AUTOSAR XML (schema 4-2-2)
package /STELLANTIS/EPT/SASWCs
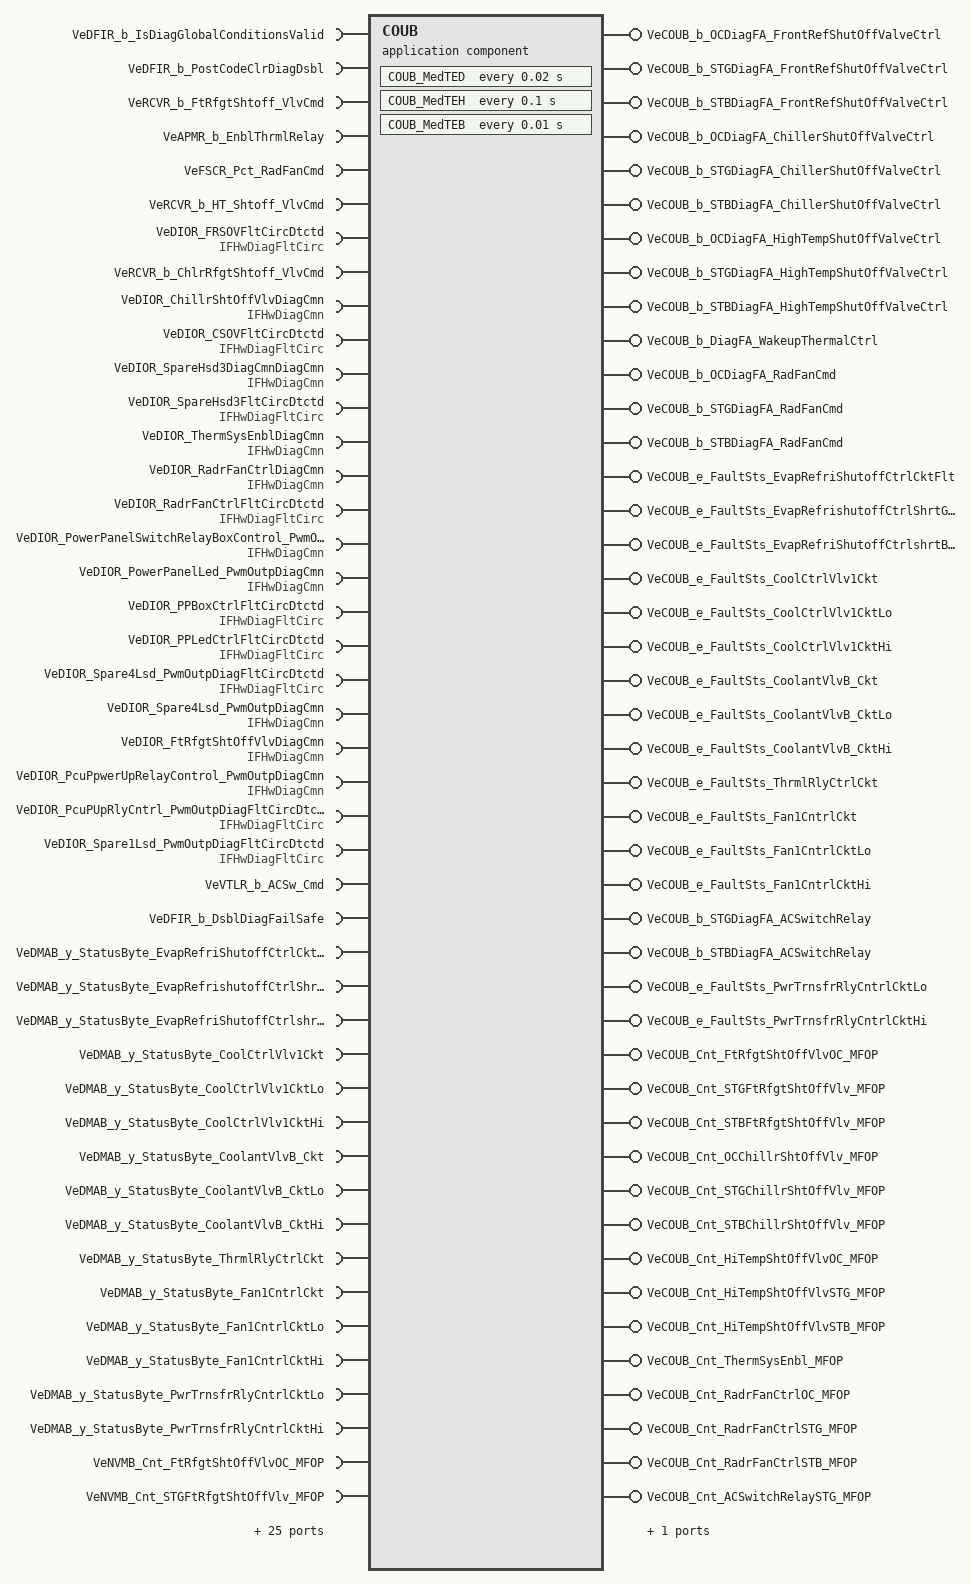
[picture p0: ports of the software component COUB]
  application sw component type COUB
    57 x require port:
      VeDFIR_b_IsDiagGlobalConditionsValid: variation-point={short-label=vpVeDFIR_b_IsDiagGlobalConditionsValid, sw-syscond=1}, nonqueued-receiver-com-spec{data-element=Value, init-value=0}, required-interface=VeDFIR_b_IsDiagGlobalConditionsValid
      VeDFIR_b_PostCodeClrDiagDsbl: variation-point={short-label=vpVeDFIR_b_PostCodeClrDiagDsbl, sw-syscond=1}, nonqueued-receiver-com-spec{data-element=Value, init-value=0}, required-interface=VeDFIR_b_PostCodeClrDiagDsbl
      VeRCVR_b_FtRfgtShtoff_VlvCmd: variation-point={short-label=vpVeRCVR_b_FtRfgtShtoff_VlvCmd, sw-syscond=1}, nonqueued-receiver-com-spec{data-element=Value, init-value=0}, required-interface=VeRCVR_b_FtRfgtShtoff_VlvCmd
      VeAPMR_b_EnblThrmlRelay: variation-point={short-label=vpVeAPMR_b_EnblThrmlRelay, sw-syscond=1}, nonqueued-receiver-com-spec{data-element=Value, init-value=0}, required-interface=VeAPMR_b_EnblThrmlRelay
      VeFSCR_Pct_RadFanCmd: variation-point={short-label=vpVeFSCR_Pct_RadFanCmd, sw-syscond=1}, nonqueued-receiver-com-spec{data-element=Value, init-value=0}, required-interface=VeFSCR_Pct_RadFanCmd
      VeRCVR_b_HT_Shtoff_VlvCmd: variation-point={short-label=vpVeRCVR_b_HT_Shtoff_VlvCmd, sw-syscond=1}, nonqueued-receiver-com-spec{data-element=Value, init-value=0}, required-interface=VeRCVR_b_HT_Shtoff_VlvCmd
      VeDIOR_FRSOVFltCircDtctd: variation-point={short-label=vpVeDIOR_FRSOVFltCircDtctd, sw-syscond=1}, required-interface=IFHwDiagFltCirc
        required-com-specs:
          {data-element=CircShoLo, init-value={short-label=DefaultInitValue_IDTCondPresence, fields=[0, 0, 0, 0, 0, 0, 0, 0]}}
          {data-element=CircShoHi, init-value={short-label=DefaultInitValue_IDTCondPresence, fields=[0, 0, 0, 0, 0, 0, 0, 0]}}
          {data-element=CircOpen, init-value={short-label=DefaultInitValue_IDTCondPresence, fields=[0, 0, 0, 0, 0, 0, 0, 0]}}
          {data-element=ShoLoad, init-value={short-label=DefaultInitValue_IDTCondPresence, fields=[0, 0, 0, 0, 0, 0, 0, 0]}}
      VeRCVR_b_ChlrRfgtShtoff_VlvCmd: variation-point={short-label=vpVeRCVR_b_ChlrRfgtShtoff_VlvCmd, sw-syscond=1}, nonqueued-receiver-com-spec{data-element=Value, init-value=0}, required-interface=VeRCVR_b_ChlrRfgtShtoff_VlvCmd
      VeDIOR_ChillrShtOffVlvDiagCmn: variation-point={short-label=vpVeDIOR_ChillrShtOffVlvDiagCmn, sw-syscond=1}, nonqueued-receiver-com-spec{data-element=b_FailrPrsnt, init-value=0}, required-interface=IFHwDiagCmn
      VeDIOR_CSOVFltCircDtctd: variation-point={short-label=vpVeDIOR_CSOVFltCircDtctd, sw-syscond=1}, required-interface=IFHwDiagFltCirc
        required-com-specs:
          {data-element=CircShoLo, init-value={short-label=DefaultInitValue_IDTCondPresence, fields=[0, 0, 0, 0, 0, 0, 0, 0]}}
          {data-element=CircShoHi, init-value={short-label=DefaultInitValue_IDTCondPresence, fields=[0, 0, 0, 0, 0, 0, 0, 0]}}
          {data-element=CircOpen, init-value={short-label=DefaultInitValue_IDTCondPresence, fields=[0, 0, 0, 0, 0, 0, 0, 0]}}
      VeDIOR_SpareHsd3DiagCmnDiagCmn: variation-point={short-label=vpVeDIOR_SpareHsd3DiagCmnDiagCmn, sw-syscond=1}, nonqueued-receiver-com-spec{data-element=b_FailrPrsnt, init-value=0}, required-interface=IFHwDiagCmn
      VeDIOR_SpareHsd3FltCircDtctd: variation-point={short-label=vpVeDIOR_SpareHsd3FltCircDtctd, sw-syscond=1}, required-interface=IFHwDiagFltCirc
        required-com-specs:
          {data-element=CircShoLo, init-value={short-label=DefaultInitValue_IDTCondPresence, fields=[0, 0, 0, 0, 0, 0, 0, 0]}}
          {data-element=CircShoHi, init-value={short-label=DefaultInitValue_IDTCondPresence, fields=[0, 0, 0, 0, 0, 0, 0, 0]}}
          {data-element=CircOpen, init-value={short-label=DefaultInitValue_IDTCondPresence, fields=[0, 0, 0, 0, 0, 0, 0, 0]}}
      VeDIOR_ThermSysEnblDiagCmn: variation-point={short-label=vpVeDIOR_ThermSysEnblDiagCmn, sw-syscond=1}, nonqueued-receiver-com-spec{data-element=b_FailrPrsnt, init-value=0}, required-interface=IFHwDiagCmn
      VeDIOR_RadrFanCtrlDiagCmn: variation-point={short-label=vpVeDIOR_RadrFanCtrlDiagCmn, sw-syscond=1}, nonqueued-receiver-com-spec{data-element=b_FailrPrsnt, init-value=0}, required-interface=IFHwDiagCmn
      VeDIOR_RadrFanCtrlFltCircDtctd: variation-point={short-label=vpVeDIOR_RadrFanCtrlFltCircDtctd, sw-syscond=1}, required-interface=IFHwDiagFltCirc
        required-com-specs:
          {data-element=CircShoLo, init-value={short-label=DefaultInitValue_IDTCondPresence, fields=[0, 0, 0, 0, 0, 0, 0, 0]}}
          {data-element=CircShoHi, init-value={short-label=DefaultInitValue_IDTCondPresence, fields=[0, 0, 0, 0, 0, 0, 0, 0]}}
          {data-element=CircOpen, init-value={short-label=DefaultInitValue_IDTCondPresence, fields=[0, 0, 0, 0, 0, 0, 0, 0]}}
      VeDIOR_PowerPanelSwitchRelayBoxControl_PwmOutpDiagCmn: nonqueued-receiver-com-spec{data-element=b_FailrPrsnt, init-value=0}, required-interface=IFHwDiagCmn
      VeDIOR_PowerPanelLed_PwmOutpDiagCmn: nonqueued-receiver-com-spec{data-element=b_FailrPrsnt, init-value=0}, required-interface=IFHwDiagCmn
      VeDIOR_PPBoxCtrlFltCircDtctd: required-interface=IFHwDiagFltCirc
        required-com-specs:
          {data-element=CircShoLo, init-value={short-label=DefaultInitValue_IDTCondPresence, fields=[0, 0, 0, 0, 0, 0, 0, 0]}}
          {data-element=CircShoHi, init-value={short-label=DefaultInitValue_IDTCondPresence, fields=[0, 0, 0, 0, 0, 0, 0, 0]}}
          {data-element=CircOpen, init-value={short-label=DefaultInitValue_IDTCondPresence, fields=[0, 0, 0, 0, 0, 0, 0, 0]}}
      VeDIOR_PPLedCtrlFltCircDtctd: required-interface=IFHwDiagFltCirc
        required-com-specs:
          {data-element=CircShoLo, init-value={short-label=DefaultInitValue_IDTCondPresence, fields=[0, 0, 0, 0, 0, 0, 0, 0]}}
          {data-element=CircShoHi, init-value={short-label=DefaultInitValue_IDTCondPresence, fields=[0, 0, 0, 0, 0, 0, 0, 0]}}
          {data-element=CircOpen, init-value={short-label=DefaultInitValue_IDTCondPresence, fields=[0, 0, 0, 0, 0, 0, 0, 0]}}
      VeDIOR_Spare4Lsd_PwmOutpDiagFltCircDtctd: variation-point={short-label=vpVeDIOR_Spare4Lsd_PwmOutpDiagFltCircDtctd, sw-syscond=1}, required-interface=IFHwDiagFltCirc
        required-com-specs:
          {data-element=CircShoLo, init-value={short-label=DefaultInitValue_IDTCondPresence, fields=[0, 0, 0, 0, 0, 0, 0, 0]}}
          {data-element=CircShoHi, init-value={short-label=DefaultInitValue_IDTCondPresence, fields=[0, 0, 0, 0, 0, 0, 0, 0]}}
          {data-element=CircOpen, init-value={short-label=DefaultInitValue_IDTCondPresence, fields=[0, 0, 0, 0, 0, 0, 0, 0]}}
      VeDIOR_Spare4Lsd_PwmOutpDiagCmn: variation-point={short-label=vpVeDIOR_Spare4Lsd_PwmOutpDiagCmn, sw-syscond=1}, nonqueued-receiver-com-spec{data-element=b_FailrPrsnt, init-value=0}, required-interface=IFHwDiagCmn
      VeDIOR_FtRfgtShtOffVlvDiagCmn: variation-point={short-label=vpVeDIOR_FtRfgtShtOffVlvDiagCmn, sw-syscond=1}, nonqueued-receiver-com-spec{data-element=b_FailrPrsnt, init-value=0}, required-interface=IFHwDiagCmn
      VeDIOR_PcuPpwerUpRelayControl_PwmOutpDiagCmn: nonqueued-receiver-com-spec{data-element=b_FailrPrsnt, init-value=0}, required-interface=IFHwDiagCmn
      VeDIOR_PcuPUpRlyCntrl_PwmOutpDiagFltCircDtctd: required-interface=IFHwDiagFltCirc
        required-com-specs:
          {data-element=CircShoLo, init-value={short-label=DefaultInitValue_IDTCondPresence, fields=[0, 0, 0, 0, 0, 0, 0, 0]}}
          {data-element=CircShoHi, init-value={short-label=DefaultInitValue_IDTCondPresence, fields=[0, 0, 0, 0, 0, 0, 0, 0]}}
          {data-element=CircOpen, init-value={short-label=DefaultInitValue_IDTCondPresence, fields=[0, 0, 0, 0, 0, 0, 0, 0]}}
      VeDIOR_Spare1Lsd_PwmOutpDiagFltCircDtctd: required-interface=IFHwDiagFltCirc
        required-com-specs:
          {data-element=CircShoLo, init-value={short-label=DefaultInitValue_IDTCondPresence, fields=[0, 0, 0, 0, 0, 0, 0, 0]}}
          {data-element=CircShoHi, init-value={short-label=DefaultInitValue_IDTCondPresence, fields=[0, 0, 0, 0, 0, 0, 0, 0]}}
          {data-element=CircOpen, init-value={short-label=DefaultInitValue_IDTCondPresence, fields=[0, 0, 0, 0, 0, 0, 0, 0]}}
      VeVTLR_b_ACSw_Cmd: variation-point={short-label=vpVeVTLR_b_ACSw_Cmd, sw-syscond=1}, nonqueued-receiver-com-spec{data-element=Value, init-value=0}, required-interface=VeVTLR_b_ACSw_Cmd
      VeDFIR_b_DsblDiagFailSafe: variation-point={short-label=vpVeDFIR_b_DsblDiagFailSafe, sw-syscond=1}, nonqueued-receiver-com-spec{data-element=Value, init-value=0}, required-interface=VeDFIR_b_DsblDiagFailSafe
      VeDMAB_y_StatusByte_EvapRefriShutoffCtrlCktFlt: variation-point={short-label=vpVeDMAB_y_StatusByte_EvapRefriShutoffCtrlCktFlt, sw-syscond=1}, nonqueued-receiver-com-spec{data-element=Value, init-value=0}, required-interface=VeDMAB_y_StatusByte_EvapRefriShutoffCtrlCktFlt
      VeDMAB_y_StatusByte_EvapRefrishutoffCtrlShrtGndFlt: variation-point={short-label=vpVeDMAB_y_StatusByte_EvapRefrishutoffCtrlShrtGndFlt, sw-syscond=1}, nonqueued-receiver-com-spec{data-element=Value, init-value=0}, required-interface=VeDMAB_y_StatusByte_EvapRefrishutoffCtrlShrtGndFlt
      VeDMAB_y_StatusByte_EvapRefriShutoffCtrlshrtBattFlt: variation-point={short-label=vpVeDMAB_y_StatusByte_EvapRefriShutoffCtrlshrtBattFlt, sw-syscond=1}, nonqueued-receiver-com-spec{data-element=Value, init-value=0}, required-interface=VeDMAB_y_StatusByte_EvapRefriShutoffCtrlshrtBattFlt
      VeDMAB_y_StatusByte_CoolCtrlVlv1Ckt: variation-point={short-label=vpVeDMAB_y_StatusByte_CoolCtrlVlv1Ckt, sw-syscond=1}, nonqueued-receiver-com-spec{data-element=Value, init-value=0}, required-interface=VeDMAB_y_StatusByte_CoolCtrlVlv1Ckt
      VeDMAB_y_StatusByte_CoolCtrlVlv1CktLo: variation-point={short-label=vpVeDMAB_y_StatusByte_CoolCtrlVlv1CktLo, sw-syscond=1}, nonqueued-receiver-com-spec{data-element=Value, init-value=0}, required-interface=VeDMAB_y_StatusByte_CoolCtrlVlv1CktLo
      VeDMAB_y_StatusByte_CoolCtrlVlv1CktHi: variation-point={short-label=vpVeDMAB_y_StatusByte_CoolCtrlVlv1CktHi, sw-syscond=1}, nonqueued-receiver-com-spec{data-element=Value, init-value=0}, required-interface=VeDMAB_y_StatusByte_CoolCtrlVlv1CktHi
      VeDMAB_y_StatusByte_CoolantVlvB_Ckt: variation-point={short-label=vpVeDMAB_y_StatusByte_CoolantVlvB_Ckt, sw-syscond=1}, nonqueued-receiver-com-spec{data-element=Value, init-value=0}, required-interface=VeDMAB_y_StatusByte_CoolantVlvB_Ckt
      VeDMAB_y_StatusByte_CoolantVlvB_CktLo: variation-point={short-label=vpVeDMAB_y_StatusByte_CoolantVlvB_CktLo, sw-syscond=1}, nonqueued-receiver-com-spec{data-element=Value, init-value=0}, required-interface=VeDMAB_y_StatusByte_CoolantVlvB_CktLo
      VeDMAB_y_StatusByte_CoolantVlvB_CktHi: variation-point={short-label=vpVeDMAB_y_StatusByte_CoolantVlvB_CktHi, sw-syscond=1}, nonqueued-receiver-com-spec{data-element=Value, init-value=0}, required-interface=VeDMAB_y_StatusByte_CoolantVlvB_CktHi
      VeDMAB_y_StatusByte_ThrmlRlyCtrlCkt: variation-point={short-label=vpVeDMAB_y_StatusByte_ThrmlRlyCtrlCkt, sw-syscond=1}, nonqueued-receiver-com-spec{data-element=Value, init-value=0}, required-interface=VeDMAB_y_StatusByte_ThrmlRlyCtrlCkt
      VeDMAB_y_StatusByte_Fan1CntrlCkt: variation-point={short-label=vpVeDMAB_y_StatusByte_Fan1CntrlCkt, sw-syscond=1}, nonqueued-receiver-com-spec{data-element=Value, init-value=0}, required-interface=VeDMAB_y_StatusByte_Fan1CntrlCkt
      VeDMAB_y_StatusByte_Fan1CntrlCktLo: variation-point={short-label=vpVeDMAB_y_StatusByte_Fan1CntrlCktLo, sw-syscond=1}, nonqueued-receiver-com-spec{data-element=Value, init-value=0}, required-interface=VeDMAB_y_StatusByte_Fan1CntrlCktLo
      VeDMAB_y_StatusByte_Fan1CntrlCktHi: variation-point={short-label=vpVeDMAB_y_StatusByte_Fan1CntrlCktHi, sw-syscond=1}, nonqueued-receiver-com-spec{data-element=Value, init-value=0}, required-interface=VeDMAB_y_StatusByte_Fan1CntrlCktHi
      VeDMAB_y_StatusByte_PwrTrnsfrRlyCntrlCktLo: variation-point={short-label=vpVeDMAB_y_StatusByte_PwrTrnsfrRlyCntrlCktLo, sw-syscond=1}, nonqueued-receiver-com-spec{data-element=Value, init-value=0}, required-interface=VeDMAB_y_StatusByte_PwrTrnsfrRlyCntrlCktLo
      VeDMAB_y_StatusByte_PwrTrnsfrRlyCntrlCktHi: variation-point={short-label=vpVeDMAB_y_StatusByte_PwrTrnsfrRlyCntrlCktHi, sw-syscond=1}, nonqueued-receiver-com-spec{data-element=Value, init-value=0}, required-interface=VeDMAB_y_StatusByte_PwrTrnsfrRlyCntrlCktHi
      VeNVMB_Cnt_FtRfgtShtOffVlvOC_MFOP: variation-point={short-label=vpVeNVMB_Cnt_FtRfgtShtOffVlvOC_MFOP, sw-syscond=1}, nonqueued-receiver-com-spec{data-element=Value, init-value=0}, required-interface=VeNVMB_Cnt_FtRfgtShtOffVlvOC_MFOP
      VeNVMB_Cnt_STGFtRfgtShtOffVlv_MFOP: variation-point={short-label=vpVeNVMB_Cnt_STGFtRfgtShtOffVlv_MFOP, sw-syscond=1}, nonqueued-receiver-com-spec{data-element=Value, init-value=0}, required-interface=VeNVMB_Cnt_STGFtRfgtShtOffVlv_MFOP
      VeNVMB_Cnt_STBFtRfgtShtOffVlv_MFOP: variation-point={short-label=vpVeNVMB_Cnt_STBFtRfgtShtOffVlv_MFOP, sw-syscond=1}, nonqueued-receiver-com-spec{data-element=Value, init-value=0}, required-interface=VeNVMB_Cnt_STBFtRfgtShtOffVlv_MFOP
      VeNVMB_Cnt_OCChillrShtOffVlv_MFOP: variation-point={short-label=vpVeNVMB_Cnt_OCChillrShtOffVlv_MFOP, sw-syscond=1}, nonqueued-receiver-com-spec{data-element=Value, init-value=0}, required-interface=VeNVMB_Cnt_OCChillrShtOffVlv_MFOP
      VeNVMB_Cnt_STGChillrShtOffVlv_MFOP: variation-point={short-label=vpVeNVMB_Cnt_STGChillrShtOffVlv_MFOP, sw-syscond=1}, nonqueued-receiver-com-spec{data-element=Value, init-value=0}, required-interface=VeNVMB_Cnt_STGChillrShtOffVlv_MFOP
      VeNVMB_Cnt_STBChillrShtOffVlv_MFOP: variation-point={short-label=vpVeNVMB_Cnt_STBChillrShtOffVlv_MFOP, sw-syscond=1}, nonqueued-receiver-com-spec{data-element=Value, init-value=0}, required-interface=VeNVMB_Cnt_STBChillrShtOffVlv_MFOP
      VeNVMB_Cnt_HiTempShtOffVlvOC_MFOP: variation-point={short-label=vpVeNVMB_Cnt_HiTempShtOffVlvOC_MFOP, sw-syscond=1}, nonqueued-receiver-com-spec{data-element=Value, init-value=0}, required-interface=VeNVMB_Cnt_HiTempShtOffVlvOC_MFOP
      VeNVMB_Cnt_HiTempShtOffVlvSTG_MFOP: variation-point={short-label=vpVeNVMB_Cnt_HiTempShtOffVlvSTG_MFOP, sw-syscond=1}, nonqueued-receiver-com-spec{data-element=Value, init-value=0}, required-interface=VeNVMB_Cnt_HiTempShtOffVlvSTG_MFOP
      VeNVMB_Cnt_HiTempShtOffVlvSTB_MFOP: variation-point={short-label=vpVeNVMB_Cnt_HiTempShtOffVlvSTB_MFOP, sw-syscond=1}, nonqueued-receiver-com-spec{data-element=Value, init-value=0}, required-interface=VeNVMB_Cnt_HiTempShtOffVlvSTB_MFOP
      VeNVMB_Cnt_ThermSysEnbl_MFOP: variation-point={short-label=vpVeNVMB_Cnt_ThermSysEnbl_MFOP, sw-syscond=1}, nonqueued-receiver-com-spec{data-element=Value, init-value=0}, required-interface=VeNVMB_Cnt_ThermSysEnbl_MFOP
      VeNVMB_Cnt_RadrFanCtrlOC_MFOP: variation-point={short-label=vpVeNVMB_Cnt_RadrFanCtrlOC_MFOP, sw-syscond=1}, nonqueued-receiver-com-spec{data-element=Value, init-value=0}, required-interface=VeNVMB_Cnt_RadrFanCtrlOC_MFOP
      VeNVMB_Cnt_RadrFanCtrlSTG_MFOP: variation-point={short-label=vpVeNVMB_Cnt_RadrFanCtrlSTG_MFOP, sw-syscond=1}, nonqueued-receiver-com-spec{data-element=Value, init-value=0}, required-interface=VeNVMB_Cnt_RadrFanCtrlSTG_MFOP
      VeNVMB_Cnt_RadrFanCtrlSTB_MFOP: variation-point={short-label=vpVeNVMB_Cnt_RadrFanCtrlSTB_MFOP, sw-syscond=1}, nonqueued-receiver-com-spec{data-element=Value, init-value=0}, required-interface=VeNVMB_Cnt_RadrFanCtrlSTB_MFOP
      VeNVMB_Cnt_ACSwitchRelaySTG_MFOP: variation-point={short-label=vpVeNVMB_Cnt_ACSwitchRelaySTG_MFOP, sw-syscond=1}, nonqueued-receiver-com-spec{data-element=Value, init-value=0}, required-interface=VeNVMB_Cnt_ACSwitchRelaySTG_MFOP
      VeNVMB_Cnt_ACSwitchRelaySTB_MFOP: variation-point={short-label=vpVeNVMB_Cnt_ACSwitchRelaySTB_MFOP, sw-syscond=1}, nonqueued-receiver-com-spec{data-element=Value, init-value=0}, required-interface=VeNVMB_Cnt_ACSwitchRelaySTB_MFOP
    45 x provide port:
      VeCOUB_b_OCDiagFA_FrontRefShutOffValveCtrl: variation-point={short-label=vpVeCOUB_b_OCDiagFA_FrontRefShutOffValveCtrl, sw-syscond=1}, nonqueued-sender-com-spec{data-element=Value, init-value=0}, provided-interface=VeCOUB_b_OCDiagFA_FrontRefShutOffValveCtrl
      VeCOUB_b_STGDiagFA_FrontRefShutOffValveCtrl: variation-point={short-label=vpVeCOUB_b_STGDiagFA_FrontRefShutOffValveCtrl, sw-syscond=1}, nonqueued-sender-com-spec{data-element=Value, init-value=0}, provided-interface=VeCOUB_b_STGDiagFA_FrontRefShutOffValveCtrl
      VeCOUB_b_STBDiagFA_FrontRefShutOffValveCtrl: variation-point={short-label=vpVeCOUB_b_STBDiagFA_FrontRefShutOffValveCtrl, sw-syscond=1}, nonqueued-sender-com-spec{data-element=Value, init-value=0}, provided-interface=VeCOUB_b_STBDiagFA_FrontRefShutOffValveCtrl
      VeCOUB_b_OCDiagFA_ChillerShutOffValveCtrl: variation-point={short-label=vpVeCOUB_b_OCDiagFA_ChillerShutOffValveCtrl, sw-syscond=1}, nonqueued-sender-com-spec{data-element=Value, init-value=0}, provided-interface=VeCOUB_b_OCDiagFA_ChillerShutOffValveCtrl
      VeCOUB_b_STGDiagFA_ChillerShutOffValveCtrl: variation-point={short-label=vpVeCOUB_b_STGDiagFA_ChillerShutOffValveCtrl, sw-syscond=1}, nonqueued-sender-com-spec{data-element=Value, init-value=0}, provided-interface=VeCOUB_b_STGDiagFA_ChillerShutOffValveCtrl
      VeCOUB_b_STBDiagFA_ChillerShutOffValveCtrl: variation-point={short-label=vpVeCOUB_b_STBDiagFA_ChillerShutOffValveCtrl, sw-syscond=1}, nonqueued-sender-com-spec{data-element=Value, init-value=0}, provided-interface=VeCOUB_b_STBDiagFA_ChillerShutOffValveCtrl
      VeCOUB_b_OCDiagFA_HighTempShutOffValveCtrl: variation-point={short-label=vpVeCOUB_b_OCDiagFA_HighTempShutOffValveCtrl, sw-syscond=1}, nonqueued-sender-com-spec{data-element=Value, init-value=0}, provided-interface=VeCOUB_b_OCDiagFA_HighTempShutOffValveCtrl
      VeCOUB_b_STGDiagFA_HighTempShutOffValveCtrl: variation-point={short-label=vpVeCOUB_b_STGDiagFA_HighTempShutOffValveCtrl, sw-syscond=1}, nonqueued-sender-com-spec{data-element=Value, init-value=0}, provided-interface=VeCOUB_b_STGDiagFA_HighTempShutOffValveCtrl
      VeCOUB_b_STBDiagFA_HighTempShutOffValveCtrl: variation-point={short-label=vpVeCOUB_b_STBDiagFA_HighTempShutOffValveCtrl, sw-syscond=1}, nonqueued-sender-com-spec{data-element=Value, init-value=0}, provided-interface=VeCOUB_b_STBDiagFA_HighTempShutOffValveCtrl
      VeCOUB_b_DiagFA_WakeupThermalCtrl: variation-point={short-label=vpVeCOUB_b_DiagFA_WakeupThermalCtrl, sw-syscond=1}, nonqueued-sender-com-spec{data-element=Value, init-value=0}, provided-interface=VeCOUB_b_DiagFA_WakeupThermalCtrl
      VeCOUB_b_OCDiagFA_RadFanCmd: variation-point={short-label=vpVeCOUB_b_OCDiagFA_RadFanCmd, sw-syscond=1}, nonqueued-sender-com-spec{data-element=Value, init-value=0}, provided-interface=VeCOUB_b_OCDiagFA_RadFanCmd
      VeCOUB_b_STGDiagFA_RadFanCmd: variation-point={short-label=vpVeCOUB_b_STGDiagFA_RadFanCmd, sw-syscond=1}, nonqueued-sender-com-spec{data-element=Value, init-value=0}, provided-interface=VeCOUB_b_STGDiagFA_RadFanCmd
      VeCOUB_b_STBDiagFA_RadFanCmd: variation-point={short-label=vpVeCOUB_b_STBDiagFA_RadFanCmd, sw-syscond=1}, nonqueued-sender-com-spec{data-element=Value, init-value=0}, provided-interface=VeCOUB_b_STBDiagFA_RadFanCmd
      VeCOUB_e_FaultSts_EvapRefriShutoffCtrlCktFlt: variation-point={short-label=vpVeCOUB_e_FaultSts_EvapRefriShutoffCtrlCktFlt, sw-syscond=1}, nonqueued-sender-com-spec{data-element=Value, init-value=CeDFIB_e_Init}, provided-interface=VeCOUB_e_FaultSts_EvapRefriShutoffCtrlCktFlt
      VeCOUB_e_FaultSts_EvapRefrishutoffCtrlShrtGndFlt: variation-point={short-label=vpVeCOUB_e_FaultSts_EvapRefrishutoffCtrlShrtGndFlt, sw-syscond=1}, nonqueued-sender-com-spec{data-element=Value, init-value=CeDFIB_e_Init}, provided-interface=VeCOUB_e_FaultSts_EvapRefrishutoffCtrlShrtGndFlt
      VeCOUB_e_FaultSts_EvapRefriShutoffCtrlshrtBattFlt: variation-point={short-label=vpVeCOUB_e_FaultSts_EvapRefriShutoffCtrlshrtBattFlt, sw-syscond=1}, nonqueued-sender-com-spec{data-element=Value, init-value=CeDFIB_e_Init}, provided-interface=VeCOUB_e_FaultSts_EvapRefriShutoffCtrlshrtBattFlt
      VeCOUB_e_FaultSts_CoolCtrlVlv1Ckt: variation-point={short-label=vpVeCOUB_e_FaultSts_CoolCtrlVlv1Ckt, sw-syscond=1}, nonqueued-sender-com-spec{data-element=Value, init-value=CeDFIB_e_Init}, provided-interface=VeCOUB_e_FaultSts_CoolCtrlVlv1Ckt
      VeCOUB_e_FaultSts_CoolCtrlVlv1CktLo: variation-point={short-label=vpVeCOUB_e_FaultSts_CoolCtrlVlv1CktLo, sw-syscond=1}, nonqueued-sender-com-spec{data-element=Value, init-value=CeDFIB_e_Init}, provided-interface=VeCOUB_e_FaultSts_CoolCtrlVlv1CktLo
      VeCOUB_e_FaultSts_CoolCtrlVlv1CktHi: variation-point={short-label=vpVeCOUB_e_FaultSts_CoolCtrlVlv1CktHi, sw-syscond=1}, nonqueued-sender-com-spec{data-element=Value, init-value=CeDFIB_e_Init}, provided-interface=VeCOUB_e_FaultSts_CoolCtrlVlv1CktHi
      VeCOUB_e_FaultSts_CoolantVlvB_Ckt: variation-point={short-label=vpVeCOUB_e_FaultSts_CoolantVlvB_Ckt, sw-syscond=1}, nonqueued-sender-com-spec{data-element=Value, init-value=CeDFIB_e_Init}, provided-interface=VeCOUB_e_FaultSts_CoolantVlvB_Ckt
      VeCOUB_e_FaultSts_CoolantVlvB_CktLo: variation-point={short-label=vpVeCOUB_e_FaultSts_CoolantVlvB_CktLo, sw-syscond=1}, nonqueued-sender-com-spec{data-element=Value, init-value=CeDFIB_e_Init}, provided-interface=VeCOUB_e_FaultSts_CoolantVlvB_CktLo
      VeCOUB_e_FaultSts_CoolantVlvB_CktHi: variation-point={short-label=vpVeCOUB_e_FaultSts_CoolantVlvB_CktHi, sw-syscond=1}, nonqueued-sender-com-spec{data-element=Value, init-value=CeDFIB_e_Init}, provided-interface=VeCOUB_e_FaultSts_CoolantVlvB_CktHi
      VeCOUB_e_FaultSts_ThrmlRlyCtrlCkt: variation-point={short-label=vpVeCOUB_e_FaultSts_ThrmlRlyCtrlCkt, sw-syscond=1}, nonqueued-sender-com-spec{data-element=Value, init-value=CeDFIB_e_Init}, provided-interface=VeCOUB_e_FaultSts_ThrmlRlyCtrlCkt
      VeCOUB_e_FaultSts_Fan1CntrlCkt: variation-point={short-label=vpVeCOUB_e_FaultSts_Fan1CntrlCkt, sw-syscond=1}, nonqueued-sender-com-spec{data-element=Value, init-value=CeDFIB_e_Init}, provided-interface=VeCOUB_e_FaultSts_Fan1CntrlCkt
      VeCOUB_e_FaultSts_Fan1CntrlCktLo: variation-point={short-label=vpVeCOUB_e_FaultSts_Fan1CntrlCktLo, sw-syscond=1}, nonqueued-sender-com-spec{data-element=Value, init-value=CeDFIB_e_Init}, provided-interface=VeCOUB_e_FaultSts_Fan1CntrlCktLo
      VeCOUB_e_FaultSts_Fan1CntrlCktHi: variation-point={short-label=vpVeCOUB_e_FaultSts_Fan1CntrlCktHi, sw-syscond=1}, nonqueued-sender-com-spec{data-element=Value, init-value=CeDFIB_e_Init}, provided-interface=VeCOUB_e_FaultSts_Fan1CntrlCktHi
      VeCOUB_b_STGDiagFA_ACSwitchRelay: variation-point={short-label=vpVeCOUB_b_STGDiagFA_ACSwitchRelay, sw-syscond=1}, nonqueued-sender-com-spec{data-element=Value, init-value=0}, provided-interface=VeCOUB_b_STGDiagFA_ACSwitchRelay
      VeCOUB_b_STBDiagFA_ACSwitchRelay: variation-point={short-label=vpVeCOUB_b_STBDiagFA_ACSwitchRelay, sw-syscond=1}, nonqueued-sender-com-spec{data-element=Value, init-value=0}, provided-interface=VeCOUB_b_STBDiagFA_ACSwitchRelay
      VeCOUB_e_FaultSts_PwrTrnsfrRlyCntrlCktLo: variation-point={short-label=vpVeCOUB_e_FaultSts_PwrTrnsfrRlyCntrlCktLo, sw-syscond=1}, nonqueued-sender-com-spec{data-element=Value, init-value=CeDFIB_e_Init}, provided-interface=VeCOUB_e_FaultSts_PwrTrnsfrRlyCntrlCktLo
      VeCOUB_e_FaultSts_PwrTrnsfrRlyCntrlCktHi: variation-point={short-label=vpVeCOUB_e_FaultSts_PwrTrnsfrRlyCntrlCktHi, sw-syscond=1}, nonqueued-sender-com-spec{data-element=Value, init-value=CeDFIB_e_Init}, provided-interface=VeCOUB_e_FaultSts_PwrTrnsfrRlyCntrlCktHi
      VeCOUB_Cnt_FtRfgtShtOffVlvOC_MFOP: variation-point={short-label=vpVeCOUB_Cnt_FtRfgtShtOffVlvOC_MFOP, sw-syscond=1}, nonqueued-sender-com-spec{data-element=Value, init-value=0}, provided-interface=VeCOUB_Cnt_FtRfgtShtOffVlvOC_MFOP
      VeCOUB_Cnt_STGFtRfgtShtOffVlv_MFOP: variation-point={short-label=vpVeCOUB_Cnt_STGFtRfgtShtOffVlv_MFOP, sw-syscond=1}, nonqueued-sender-com-spec{data-element=Value, init-value=0}, provided-interface=VeCOUB_Cnt_STGFtRfgtShtOffVlv_MFOP
      VeCOUB_Cnt_STBFtRfgtShtOffVlv_MFOP: variation-point={short-label=vpVeCOUB_Cnt_STBFtRfgtShtOffVlv_MFOP, sw-syscond=1}, nonqueued-sender-com-spec{data-element=Value, init-value=0}, provided-interface=VeCOUB_Cnt_STBFtRfgtShtOffVlv_MFOP
      VeCOUB_Cnt_OCChillrShtOffVlv_MFOP: variation-point={short-label=vpVeCOUB_Cnt_OCChillrShtOffVlv_MFOP, sw-syscond=1}, nonqueued-sender-com-spec{data-element=Value, init-value=0}, provided-interface=VeCOUB_Cnt_OCChillrShtOffVlv_MFOP
      VeCOUB_Cnt_STGChillrShtOffVlv_MFOP: variation-point={short-label=vpVeCOUB_Cnt_STGChillrShtOffVlv_MFOP, sw-syscond=1}, nonqueued-sender-com-spec{data-element=Value, init-value=0}, provided-interface=VeCOUB_Cnt_STGChillrShtOffVlv_MFOP
      VeCOUB_Cnt_STBChillrShtOffVlv_MFOP: variation-point={short-label=vpVeCOUB_Cnt_STBChillrShtOffVlv_MFOP, sw-syscond=1}, nonqueued-sender-com-spec{data-element=Value, init-value=0}, provided-interface=VeCOUB_Cnt_STBChillrShtOffVlv_MFOP
      VeCOUB_Cnt_HiTempShtOffVlvOC_MFOP: variation-point={short-label=vpVeCOUB_Cnt_HiTempShtOffVlvOC_MFOP, sw-syscond=1}, nonqueued-sender-com-spec{data-element=Value, init-value=0}, provided-interface=VeCOUB_Cnt_HiTempShtOffVlvOC_MFOP
      VeCOUB_Cnt_HiTempShtOffVlvSTG_MFOP: variation-point={short-label=vpVeCOUB_Cnt_HiTempShtOffVlvSTG_MFOP, sw-syscond=1}, nonqueued-sender-com-spec{data-element=Value, init-value=0}, provided-interface=VeCOUB_Cnt_HiTempShtOffVlvSTG_MFOP
      VeCOUB_Cnt_HiTempShtOffVlvSTB_MFOP: variation-point={short-label=vpVeCOUB_Cnt_HiTempShtOffVlvSTB_MFOP, sw-syscond=1}, nonqueued-sender-com-spec{data-element=Value, init-value=0}, provided-interface=VeCOUB_Cnt_HiTempShtOffVlvSTB_MFOP
      VeCOUB_Cnt_ThermSysEnbl_MFOP: variation-point={short-label=vpVeCOUB_Cnt_ThermSysEnbl_MFOP, sw-syscond=1}, nonqueued-sender-com-spec{data-element=Value, init-value=0}, provided-interface=VeCOUB_Cnt_ThermSysEnbl_MFOP
      VeCOUB_Cnt_RadrFanCtrlOC_MFOP: variation-point={short-label=vpVeCOUB_Cnt_RadrFanCtrlOC_MFOP, sw-syscond=1}, nonqueued-sender-com-spec{data-element=Value, init-value=0}, provided-interface=VeCOUB_Cnt_RadrFanCtrlOC_MFOP
      VeCOUB_Cnt_RadrFanCtrlSTG_MFOP: variation-point={short-label=vpVeCOUB_Cnt_RadrFanCtrlSTG_MFOP, sw-syscond=1}, nonqueued-sender-com-spec{data-element=Value, init-value=0}, provided-interface=VeCOUB_Cnt_RadrFanCtrlSTG_MFOP
      VeCOUB_Cnt_RadrFanCtrlSTB_MFOP: variation-point={short-label=vpVeCOUB_Cnt_RadrFanCtrlSTB_MFOP, sw-syscond=1}, nonqueued-sender-com-spec{data-element=Value, init-value=0}, provided-interface=VeCOUB_Cnt_RadrFanCtrlSTB_MFOP
      VeCOUB_Cnt_ACSwitchRelaySTG_MFOP: variation-point={short-label=vpVeCOUB_Cnt_ACSwitchRelaySTG_MFOP, sw-syscond=1}, nonqueued-sender-com-spec{data-element=Value, init-value=0}, provided-interface=VeCOUB_Cnt_ACSwitchRelaySTG_MFOP
      VeCOUB_Cnt_ACSwitchRelaySTB_MFOP: variation-point={short-label=vpVeCOUB_Cnt_ACSwitchRelaySTB_MFOP, sw-syscond=1}, nonqueued-sender-com-spec{data-element=Value, init-value=0}, provided-interface=VeCOUB_Cnt_ACSwitchRelaySTB_MFOP
    12 x require port:
      SetDIOR_b_ChillrShtOffVlv: variation-point={short-label=vpSetDIOR_b_ChillrShtOffVlv, sw-syscond=1}, client-com-spec=St, required-interface=IFIoHwAbDigOutpSetSt
      SetDIOR_b_FrntRefrigShtOffVlv: variation-point={short-label=vpSetDIOR_b_FrntRefrigShtOffVlv, sw-syscond=1}, client-com-spec=St, required-interface=IFIoHwAbDigOutpSetSt
      SetDIOR_b_SpareHsd3OutpSt: variation-point={short-label=vpSetDIOR_b_SpareHsd3OutpSt, sw-syscond=1}, client-com-spec=St, required-interface=IFIoHwAbDigOutpSetSt
      SetDIOR_b_ThermSysEnbl: variation-point={short-label=vpSetDIOR_b_ThermSysEnbl, sw-syscond=1}, client-com-spec=St, required-interface=IFIoHwAbDigOutpSetSt
      COUB_MedTEH_StartCheckpoint: client-com-spec=CheckpointReached, required-interface=WdgM_LocalSupervision
      COUB_MedTEH_StopCheckpoint: client-com-spec=CheckpointReached, required-interface=WdgM_LocalSupervision
      COUB_MedTEB_StartCheckpoint: client-com-spec=CheckpointReached, required-interface=WdgM_LocalSupervision
      COUB_MedTEB_StopCheckpoint: client-com-spec=CheckpointReached, required-interface=WdgM_LocalSupervision
      COUB_MedTED_StartCheckpoint: client-com-spec=CheckpointReached, required-interface=WdgM_LocalSupervision
      COUB_MedTED_StopCheckpoint: client-com-spec=CheckpointReached, required-interface=WdgM_LocalSupervision
      SetDIOR_e_Spare4Lsd_PwmOutpOps: variation-point={short-label=vpSetDIOR_e_Spare4Lsd_PwmOutpOps, sw-syscond=1}, client-com-spec=SetDIOR_PWM_DC, required-interface=IFIoHwAbPWMOutpSet
      SetDIOR_e_RadrFanCtrl: variation-point={short-label=vpSetDIOR_e_RadrFanCtrl, sw-syscond=1}, client-com-spec=SetDIOR_PWM_DC, required-interface=IFIoHwAbPWMOutpSet
    behavior IB_COUB: data-type-mapping=[msADTtoIDTMapping, ADTtoIDTMapping], handle-termination-and-restart=NO-SUPPORT
      timing event Event_MedTED: start-on-event=COUB_MedTED, period=0.02
      timing event Event_MedTEH: start-on-event=COUB_MedTEH, period=0.1
      timing event Event_MedTEB: start-on-event=COUB_MedTEB, period=0.01
      init event Event_COUB_ac_Init: start-on-event=COUB_ac_Init
      4 x runnable:
        COUB_ac_Init
          data-send-points:
            15 x access:
              OUT_VeCOUB_e_FaultSts_EvapRefriShutoffCtrlCktFlt_Value: accessed-variable=VeCOUB_e_FaultSts_EvapRefriShutoffCtrlCktFlt.Value, variation-point={short-label=vpOUT_VeCOUB_e_FaultSts_EvapRefriShutoffCtrlCktFlt_Value, sw-syscond=1}
              OUT_VeCOUB_e_FaultSts_EvapRefrishutoffCtrlShrtGndFlt_Value: accessed-variable=VeCOUB_e_FaultSts_EvapRefrishutoffCtrlShrtGndFlt.Value, variation-point={short-label=vpOUT_VeCOUB_e_FaultSts_EvapRefrishutoffCtrlShrtGndFlt_Value, sw-syscond=1}
              OUT_VeCOUB_e_FaultSts_EvapRefriShutoffCtrlshrtBattFlt_Value: accessed-variable=VeCOUB_e_FaultSts_EvapRefriShutoffCtrlshrtBattFlt.Value, variation-point={short-label=vpOUT_VeCOUB_e_FaultSts_EvapRefriShutoffCtrlshrtBattFlt_Value, sw-syscond=1}
              OUT_VeCOUB_e_FaultSts_CoolCtrlVlv1Ckt_Value: accessed-variable=VeCOUB_e_FaultSts_CoolCtrlVlv1Ckt.Value, variation-point={short-label=vpOUT_VeCOUB_e_FaultSts_CoolCtrlVlv1Ckt_Value, sw-syscond=1}
              OUT_VeCOUB_e_FaultSts_CoolCtrlVlv1CktLo_Value: accessed-variable=VeCOUB_e_FaultSts_CoolCtrlVlv1CktLo.Value, variation-point={short-label=vpOUT_VeCOUB_e_FaultSts_CoolCtrlVlv1CktLo_Value, sw-syscond=1}
              OUT_VeCOUB_e_FaultSts_CoolCtrlVlv1CktHi_Value: accessed-variable=VeCOUB_e_FaultSts_CoolCtrlVlv1CktHi.Value, variation-point={short-label=vpOUT_VeCOUB_e_FaultSts_CoolCtrlVlv1CktHi_Value, sw-syscond=1}
              OUT_VeCOUB_e_FaultSts_CoolantVlvB_Ckt_Value: accessed-variable=VeCOUB_e_FaultSts_CoolantVlvB_Ckt.Value, variation-point={short-label=vpOUT_VeCOUB_e_FaultSts_CoolantVlvB_Ckt_Value, sw-syscond=1}
              OUT_VeCOUB_e_FaultSts_CoolantVlvB_CktLo_Value: accessed-variable=VeCOUB_e_FaultSts_CoolantVlvB_CktLo.Value, variation-point={short-label=vpOUT_VeCOUB_e_FaultSts_CoolantVlvB_CktLo_Value, sw-syscond=1}
              OUT_VeCOUB_e_FaultSts_CoolantVlvB_CktHi_Value: accessed-variable=VeCOUB_e_FaultSts_CoolantVlvB_CktHi.Value, variation-point={short-label=vpOUT_VeCOUB_e_FaultSts_CoolantVlvB_CktHi_Value, sw-syscond=1}
              OUT_VeCOUB_e_FaultSts_ThrmlRlyCtrlCkt_Value: accessed-variable=VeCOUB_e_FaultSts_ThrmlRlyCtrlCkt.Value, variation-point={short-label=vpOUT_VeCOUB_e_FaultSts_ThrmlRlyCtrlCkt_Value, sw-syscond=1}
              OUT_VeCOUB_e_FaultSts_Fan1CntrlCkt_Value: accessed-variable=VeCOUB_e_FaultSts_Fan1CntrlCkt.Value, variation-point={short-label=vpOUT_VeCOUB_e_FaultSts_Fan1CntrlCkt_Value, sw-syscond=1}
              OUT_VeCOUB_e_FaultSts_Fan1CntrlCktLo_Value: accessed-variable=VeCOUB_e_FaultSts_Fan1CntrlCktLo.Value, variation-point={short-label=vpOUT_VeCOUB_e_FaultSts_Fan1CntrlCktLo_Value, sw-syscond=1}
              OUT_VeCOUB_e_FaultSts_Fan1CntrlCktHi_Value: accessed-variable=VeCOUB_e_FaultSts_Fan1CntrlCktHi.Value, variation-point={short-label=vpOUT_VeCOUB_e_FaultSts_Fan1CntrlCktHi_Value, sw-syscond=1}
              OUT_VeCOUB_e_FaultSts_PwrTrnsfrRlyCntrlCktLo_Value: accessed-variable=VeCOUB_e_FaultSts_PwrTrnsfrRlyCntrlCktLo.Value, variation-point={short-label=vpOUT_VeCOUB_e_FaultSts_PwrTrnsfrRlyCntrlCktLo_Value, sw-syscond=1}
              OUT_VeCOUB_e_FaultSts_PwrTrnsfrRlyCntrlCktHi_Value: accessed-variable=VeCOUB_e_FaultSts_PwrTrnsfrRlyCntrlCktHi.Value, variation-point={short-label=vpOUT_VeCOUB_e_FaultSts_PwrTrnsfrRlyCntrlCktHi_Value, sw-syscond=1}
          10 x sync call, all with timeout=1E-06:
            SC_SetDIOR_b_ChillrShtOffVlv_St: operation=SetDIOR_b_ChillrShtOffVlv.St, variation-point={short-label=vpSC_SetDIOR_b_ChillrShtOffVlv_St, sw-syscond=1}
            SC_SetDIOR_b_FrntRefrigShtOffVlv_St: operation=SetDIOR_b_FrntRefrigShtOffVlv.St, variation-point={short-label=vpSC_SetDIOR_b_FrntRefrigShtOffVlv_St, sw-syscond=1}
            SC_SetDIOR_b_SpareHsd3OutpSt_St: operation=SetDIOR_b_SpareHsd3OutpSt.St, variation-point={short-label=vpSC_SetDIOR_b_SpareHsd3OutpSt_St, sw-syscond=1}
            SC_SetDIOR_b_ThermSysEnbl_St: operation=SetDIOR_b_ThermSysEnbl.St, variation-point={short-label=vpSC_SetDIOR_b_ThermSysEnbl_St, sw-syscond=1}
            SC_SetDIOR_e_RadrFanCtrl_SetDIOR_PWM_Pol: operation=SetDIOR_e_RadrFanCtrl.SetDIOR_PWM_Pol, variation-point={short-label=vpSC_SetDIOR_e_RadrFanCtrl_SetDIOR_PWM_Pol, sw-syscond=1}
            SC_SetDIOR_e_RadrFanCtrl_SetDIOR_PWM_Prd: operation=SetDIOR_e_RadrFanCtrl.SetDIOR_PWM_Prd, variation-point={short-label=vpSC_SetDIOR_e_RadrFanCtrl_SetDIOR_PWM_Prd, sw-syscond=1}
            SC_SetDIOR_e_RadrFanCtrl_SetEnblSt: operation=SetDIOR_e_RadrFanCtrl.SetEnblSt, variation-point={short-label=vpSC_SetDIOR_e_RadrFanCtrl_SetEnblSt, sw-syscond=1}
            SC_SetDIOR_e_Spare4Lsd_PwmOutpOps_SetDIOR_PWM_Pol: operation=SetDIOR_e_Spare4Lsd_PwmOutpOps.SetDIOR_PWM_Pol, variation-point={short-label=vpSC_SetDIOR_e_Spare4Lsd_PwmOutpOps_SetDIOR_PWM_Pol, sw-syscond=1}
            SC_SetDIOR_e_Spare4Lsd_PwmOutpOps_SetDIOR_PWM_Prd: operation=SetDIOR_e_Spare4Lsd_PwmOutpOps.SetDIOR_PWM_Prd, variation-point={short-label=vpSC_SetDIOR_e_Spare4Lsd_PwmOutpOps_SetDIOR_PWM_Prd, sw-syscond=1}
            SC_SetDIOR_e_Spare4Lsd_PwmOutpOps_SetEnblSt: operation=SetDIOR_e_Spare4Lsd_PwmOutpOps.SetEnblSt, variation-point={short-label=vpSC_SetDIOR_e_Spare4Lsd_PwmOutpOps_SetEnblSt, sw-syscond=1}
        COUB_MedTED
          data-receive-point-by-arguments:
            36 x access:
              IN_VeDFIR_b_DsblDiagFailSafe_Value: accessed-variable=VeDFIR_b_DsblDiagFailSafe.Value, variation-point={short-label=vpIN_VeDFIR_b_DsblDiagFailSafe_Value, sw-syscond=1}
              IN_VeDFIR_b_IsDiagGlobalConditionsValid_Value: accessed-variable=VeDFIR_b_IsDiagGlobalConditionsValid.Value, variation-point={short-label=vpIN_VeDFIR_b_IsDiagGlobalConditionsValid_Value, sw-syscond=1}
              IN_VeDFIR_b_PostCodeClrDiagDsbl_Value: accessed-variable=VeDFIR_b_PostCodeClrDiagDsbl.Value, variation-point={short-label=vpIN_VeDFIR_b_PostCodeClrDiagDsbl_Value, sw-syscond=1}
              IN_VeDIOR_CSOVFltCircDtctd_CircOpen: accessed-variable=VeDIOR_CSOVFltCircDtctd.CircOpen, variation-point={short-label=vpIN_VeDIOR_CSOVFltCircDtctd_CircOpen, sw-syscond=1}
              IN_VeDIOR_CSOVFltCircDtctd_CircShoHi: accessed-variable=VeDIOR_CSOVFltCircDtctd.CircShoHi, variation-point={short-label=vpIN_VeDIOR_CSOVFltCircDtctd_CircShoHi, sw-syscond=1}
              IN_VeDIOR_CSOVFltCircDtctd_CircShoLo: accessed-variable=VeDIOR_CSOVFltCircDtctd.CircShoLo, variation-point={short-label=vpIN_VeDIOR_CSOVFltCircDtctd_CircShoLo, sw-syscond=1}
              IN_VeDIOR_ChillrShtOffVlvDiagCmn_b_FailrPrsnt: accessed-variable=VeDIOR_ChillrShtOffVlvDiagCmn.b_FailrPrsnt, variation-point={short-label=vpIN_VeDIOR_ChillrShtOffVlvDiagCmn_b_FailrPrsnt, sw-syscond=1}
              IN_VeDIOR_FRSOVFltCircDtctd_CircOpen: accessed-variable=VeDIOR_FRSOVFltCircDtctd.CircOpen, variation-point={short-label=vpIN_VeDIOR_FRSOVFltCircDtctd_CircOpen, sw-syscond=1}
              IN_VeDIOR_FRSOVFltCircDtctd_CircShoHi: accessed-variable=VeDIOR_FRSOVFltCircDtctd.CircShoHi, variation-point={short-label=vpIN_VeDIOR_FRSOVFltCircDtctd_CircShoHi, sw-syscond=1}
              IN_VeDIOR_FRSOVFltCircDtctd_CircShoLo: accessed-variable=VeDIOR_FRSOVFltCircDtctd.CircShoLo, variation-point={short-label=vpIN_VeDIOR_FRSOVFltCircDtctd_CircShoLo, sw-syscond=1}
              IN_VeDIOR_FtRfgtShtOffVlvDiagCmn_b_FailrPrsnt: accessed-variable=VeDIOR_FtRfgtShtOffVlvDiagCmn.b_FailrPrsnt, variation-point={short-label=vpIN_VeDIOR_FtRfgtShtOffVlvDiagCmn_b_FailrPrsnt, sw-syscond=1}
              IN_VeDIOR_SpareHsd3DiagCmnDiagCmn_b_FailrPrsnt: accessed-variable=VeDIOR_SpareHsd3DiagCmnDiagCmn.b_FailrPrsnt, variation-point={short-label=vpIN_VeDIOR_SpareHsd3DiagCmnDiagCmn_b_FailrPrsnt, sw-syscond=1}
              IN_VeDIOR_SpareHsd3FltCircDtctd_CircOpen: accessed-variable=VeDIOR_SpareHsd3FltCircDtctd.CircOpen, variation-point={short-label=vpIN_VeDIOR_SpareHsd3FltCircDtctd_CircOpen, sw-syscond=1}
              IN_VeDIOR_SpareHsd3FltCircDtctd_CircShoHi: accessed-variable=VeDIOR_SpareHsd3FltCircDtctd.CircShoHi, variation-point={short-label=vpIN_VeDIOR_SpareHsd3FltCircDtctd_CircShoHi, sw-syscond=1}
              IN_VeDIOR_SpareHsd3FltCircDtctd_CircShoLo: accessed-variable=VeDIOR_SpareHsd3FltCircDtctd.CircShoLo, variation-point={short-label=vpIN_VeDIOR_SpareHsd3FltCircDtctd_CircShoLo, sw-syscond=1}
              IN_VeDMAB_y_StatusByte_CoolCtrlVlv1Ckt_Value: accessed-variable=VeDMAB_y_StatusByte_CoolCtrlVlv1Ckt.Value, variation-point={short-label=vpIN_VeDMAB_y_StatusByte_CoolCtrlVlv1Ckt_Value, sw-syscond=1}
              IN_VeDMAB_y_StatusByte_CoolCtrlVlv1CktHi_Value: accessed-variable=VeDMAB_y_StatusByte_CoolCtrlVlv1CktHi.Value, variation-point={short-label=vpIN_VeDMAB_y_StatusByte_CoolCtrlVlv1CktHi_Value, sw-syscond=1}
              IN_VeDMAB_y_StatusByte_CoolCtrlVlv1CktLo_Value: accessed-variable=VeDMAB_y_StatusByte_CoolCtrlVlv1CktLo.Value, variation-point={short-label=vpIN_VeDMAB_y_StatusByte_CoolCtrlVlv1CktLo_Value, sw-syscond=1}
              IN_VeDMAB_y_StatusByte_CoolantVlvB_Ckt_Value: accessed-variable=VeDMAB_y_StatusByte_CoolantVlvB_Ckt.Value, variation-point={short-label=vpIN_VeDMAB_y_StatusByte_CoolantVlvB_Ckt_Value, sw-syscond=1}
              IN_VeDMAB_y_StatusByte_CoolantVlvB_CktHi_Value: accessed-variable=VeDMAB_y_StatusByte_CoolantVlvB_CktHi.Value, variation-point={short-label=vpIN_VeDMAB_y_StatusByte_CoolantVlvB_CktHi_Value, sw-syscond=1}
              IN_VeDMAB_y_StatusByte_CoolantVlvB_CktLo_Value: accessed-variable=VeDMAB_y_StatusByte_CoolantVlvB_CktLo.Value, variation-point={short-label=vpIN_VeDMAB_y_StatusByte_CoolantVlvB_CktLo_Value, sw-syscond=1}
              IN_VeDMAB_y_StatusByte_EvapRefriShutoffCtrlCktFlt_Value: accessed-variable=VeDMAB_y_StatusByte_EvapRefriShutoffCtrlCktFlt.Value, variation-point={short-label=vpIN_VeDMAB_y_StatusByte_EvapRefriShutoffCtrlCktFlt_Value, sw-syscond=1}
              IN_VeDMAB_y_StatusByte_EvapRefriShutoffCtrlshrtBattFlt_Value: accessed-variable=VeDMAB_y_StatusByte_EvapRefriShutoffCtrlshrtBattFlt.Value, variation-point={short-label=vpIN_VeDMAB_y_StatusByte_EvapRefriShutoffCtrlshrtBattFlt_Value, sw-syscond=1}
              IN_VeDMAB_y_StatusByte_EvapRefrishutoffCtrlShrtGndFlt_Value: accessed-variable=VeDMAB_y_StatusByte_EvapRefrishutoffCtrlShrtGndFlt.Value, variation-point={short-label=vpIN_VeDMAB_y_StatusByte_EvapRefrishutoffCtrlShrtGndFlt_Value, sw-syscond=1}
              IN_VeNVMB_Cnt_FtRfgtShtOffVlvOC_MFOP_Value: accessed-variable=VeNVMB_Cnt_FtRfgtShtOffVlvOC_MFOP.Value, variation-point={short-label=vpIN_VeNVMB_Cnt_FtRfgtShtOffVlvOC_MFOP_Value, sw-syscond=1}
              IN_VeNVMB_Cnt_HiTempShtOffVlvOC_MFOP_Value: accessed-variable=VeNVMB_Cnt_HiTempShtOffVlvOC_MFOP.Value, variation-point={short-label=vpIN_VeNVMB_Cnt_HiTempShtOffVlvOC_MFOP_Value, sw-syscond=1}
              IN_VeNVMB_Cnt_HiTempShtOffVlvSTB_MFOP_Value: accessed-variable=VeNVMB_Cnt_HiTempShtOffVlvSTB_MFOP.Value, variation-point={short-label=vpIN_VeNVMB_Cnt_HiTempShtOffVlvSTB_MFOP_Value, sw-syscond=1}
              IN_VeNVMB_Cnt_HiTempShtOffVlvSTG_MFOP_Value: accessed-variable=VeNVMB_Cnt_HiTempShtOffVlvSTG_MFOP.Value, variation-point={short-label=vpIN_VeNVMB_Cnt_HiTempShtOffVlvSTG_MFOP_Value, sw-syscond=1}
              IN_VeNVMB_Cnt_OCChillrShtOffVlv_MFOP_Value: accessed-variable=VeNVMB_Cnt_OCChillrShtOffVlv_MFOP.Value, variation-point={short-label=vpIN_VeNVMB_Cnt_OCChillrShtOffVlv_MFOP_Value, sw-syscond=1}
              IN_VeNVMB_Cnt_STBChillrShtOffVlv_MFOP_Value: accessed-variable=VeNVMB_Cnt_STBChillrShtOffVlv_MFOP.Value, variation-point={short-label=vpIN_VeNVMB_Cnt_STBChillrShtOffVlv_MFOP_Value, sw-syscond=1}
              IN_VeNVMB_Cnt_STBFtRfgtShtOffVlv_MFOP_Value: accessed-variable=VeNVMB_Cnt_STBFtRfgtShtOffVlv_MFOP.Value, variation-point={short-label=vpIN_VeNVMB_Cnt_STBFtRfgtShtOffVlv_MFOP_Value, sw-syscond=1}
              IN_VeNVMB_Cnt_STGChillrShtOffVlv_MFOP_Value: accessed-variable=VeNVMB_Cnt_STGChillrShtOffVlv_MFOP.Value, variation-point={short-label=vpIN_VeNVMB_Cnt_STGChillrShtOffVlv_MFOP_Value, sw-syscond=1}
              IN_VeNVMB_Cnt_STGFtRfgtShtOffVlv_MFOP_Value: accessed-variable=VeNVMB_Cnt_STGFtRfgtShtOffVlv_MFOP.Value, variation-point={short-label=vpIN_VeNVMB_Cnt_STGFtRfgtShtOffVlv_MFOP_Value, sw-syscond=1}
              IN_VeRCVR_b_ChlrRfgtShtoff_VlvCmd_Value: accessed-variable=VeRCVR_b_ChlrRfgtShtoff_VlvCmd.Value, variation-point={short-label=vpIN_VeRCVR_b_ChlrRfgtShtoff_VlvCmd_Value, sw-syscond=1}
              IN_VeRCVR_b_FtRfgtShtoff_VlvCmd_Value: accessed-variable=VeRCVR_b_FtRfgtShtoff_VlvCmd.Value, variation-point={short-label=vpIN_VeRCVR_b_FtRfgtShtoff_VlvCmd_Value, sw-syscond=1}
              IN_VeRCVR_b_HT_Shtoff_VlvCmd_Value: accessed-variable=VeRCVR_b_HT_Shtoff_VlvCmd.Value, variation-point={short-label=vpIN_VeRCVR_b_HT_Shtoff_VlvCmd_Value, sw-syscond=1}
          data-send-points:
            27 x access:
              OUT_VeCOUB_b_OCDiagFA_FrontRefShutOffValveCtrl_Value: accessed-variable=VeCOUB_b_OCDiagFA_FrontRefShutOffValveCtrl.Value, variation-point={short-label=vpOUT_VeCOUB_b_OCDiagFA_FrontRefShutOffValveCtrl_Value, sw-syscond=1}
              OUT_VeCOUB_b_STGDiagFA_FrontRefShutOffValveCtrl_Value: accessed-variable=VeCOUB_b_STGDiagFA_FrontRefShutOffValveCtrl.Value, variation-point={short-label=vpOUT_VeCOUB_b_STGDiagFA_FrontRefShutOffValveCtrl_Value, sw-syscond=1}
              OUT_VeCOUB_b_STBDiagFA_FrontRefShutOffValveCtrl_Value: accessed-variable=VeCOUB_b_STBDiagFA_FrontRefShutOffValveCtrl.Value, variation-point={short-label=vpOUT_VeCOUB_b_STBDiagFA_FrontRefShutOffValveCtrl_Value, sw-syscond=1}
              OUT_VeCOUB_b_OCDiagFA_ChillerShutOffValveCtrl_Value: accessed-variable=VeCOUB_b_OCDiagFA_ChillerShutOffValveCtrl.Value, variation-point={short-label=vpOUT_VeCOUB_b_OCDiagFA_ChillerShutOffValveCtrl_Value, sw-syscond=1}
              OUT_VeCOUB_b_STGDiagFA_ChillerShutOffValveCtrl_Value: accessed-variable=VeCOUB_b_STGDiagFA_ChillerShutOffValveCtrl.Value, variation-point={short-label=vpOUT_VeCOUB_b_STGDiagFA_ChillerShutOffValveCtrl_Value, sw-syscond=1}
              OUT_VeCOUB_b_STBDiagFA_ChillerShutOffValveCtrl_Value: accessed-variable=VeCOUB_b_STBDiagFA_ChillerShutOffValveCtrl.Value, variation-point={short-label=vpOUT_VeCOUB_b_STBDiagFA_ChillerShutOffValveCtrl_Value, sw-syscond=1}
              OUT_VeCOUB_b_OCDiagFA_HighTempShutOffValveCtrl_Value: accessed-variable=VeCOUB_b_OCDiagFA_HighTempShutOffValveCtrl.Value, variation-point={short-label=vpOUT_VeCOUB_b_OCDiagFA_HighTempShutOffValveCtrl_Value, sw-syscond=1}
              OUT_VeCOUB_b_STGDiagFA_HighTempShutOffValveCtrl_Value: accessed-variable=VeCOUB_b_STGDiagFA_HighTempShutOffValveCtrl.Value, variation-point={short-label=vpOUT_VeCOUB_b_STGDiagFA_HighTempShutOffValveCtrl_Value, sw-syscond=1}
              OUT_VeCOUB_b_STBDiagFA_HighTempShutOffValveCtrl_Value: accessed-variable=VeCOUB_b_STBDiagFA_HighTempShutOffValveCtrl.Value, variation-point={short-label=vpOUT_VeCOUB_b_STBDiagFA_HighTempShutOffValveCtrl_Value, sw-syscond=1}
              OUT_VeCOUB_e_FaultSts_EvapRefriShutoffCtrlCktFlt_Value: accessed-variable=VeCOUB_e_FaultSts_EvapRefriShutoffCtrlCktFlt.Value, variation-point={short-label=vpOUT_VeCOUB_e_FaultSts_EvapRefriShutoffCtrlCktFlt_Value, sw-syscond=1}
              OUT_VeCOUB_e_FaultSts_EvapRefrishutoffCtrlShrtGndFlt_Value: accessed-variable=VeCOUB_e_FaultSts_EvapRefrishutoffCtrlShrtGndFlt.Value, variation-point={short-label=vpOUT_VeCOUB_e_FaultSts_EvapRefrishutoffCtrlShrtGndFlt_Value, sw-syscond=1}
              OUT_VeCOUB_e_FaultSts_EvapRefriShutoffCtrlshrtBattFlt_Value: accessed-variable=VeCOUB_e_FaultSts_EvapRefriShutoffCtrlshrtBattFlt.Value, variation-point={short-label=vpOUT_VeCOUB_e_FaultSts_EvapRefriShutoffCtrlshrtBattFlt_Value, sw-syscond=1}
              OUT_VeCOUB_e_FaultSts_CoolCtrlVlv1Ckt_Value: accessed-variable=VeCOUB_e_FaultSts_CoolCtrlVlv1Ckt.Value, variation-point={short-label=vpOUT_VeCOUB_e_FaultSts_CoolCtrlVlv1Ckt_Value, sw-syscond=1}
              OUT_VeCOUB_e_FaultSts_CoolCtrlVlv1CktLo_Value: accessed-variable=VeCOUB_e_FaultSts_CoolCtrlVlv1CktLo.Value, variation-point={short-label=vpOUT_VeCOUB_e_FaultSts_CoolCtrlVlv1CktLo_Value, sw-syscond=1}
              OUT_VeCOUB_e_FaultSts_CoolCtrlVlv1CktHi_Value: accessed-variable=VeCOUB_e_FaultSts_CoolCtrlVlv1CktHi.Value, variation-point={short-label=vpOUT_VeCOUB_e_FaultSts_CoolCtrlVlv1CktHi_Value, sw-syscond=1}
              OUT_VeCOUB_e_FaultSts_CoolantVlvB_Ckt_Value: accessed-variable=VeCOUB_e_FaultSts_CoolantVlvB_Ckt.Value, variation-point={short-label=vpOUT_VeCOUB_e_FaultSts_CoolantVlvB_Ckt_Value, sw-syscond=1}
              OUT_VeCOUB_e_FaultSts_CoolantVlvB_CktLo_Value: accessed-variable=VeCOUB_e_FaultSts_CoolantVlvB_CktLo.Value, variation-point={short-label=vpOUT_VeCOUB_e_FaultSts_CoolantVlvB_CktLo_Value, sw-syscond=1}
              OUT_VeCOUB_e_FaultSts_CoolantVlvB_CktHi_Value: accessed-variable=VeCOUB_e_FaultSts_CoolantVlvB_CktHi.Value, variation-point={short-label=vpOUT_VeCOUB_e_FaultSts_CoolantVlvB_CktHi_Value, sw-syscond=1}
              OUT_VeCOUB_Cnt_FtRfgtShtOffVlvOC_MFOP_Value: accessed-variable=VeCOUB_Cnt_FtRfgtShtOffVlvOC_MFOP.Value, variation-point={short-label=vpOUT_VeCOUB_Cnt_FtRfgtShtOffVlvOC_MFOP_Value, sw-syscond=1}
              OUT_VeCOUB_Cnt_STGFtRfgtShtOffVlv_MFOP_Value: accessed-variable=VeCOUB_Cnt_STGFtRfgtShtOffVlv_MFOP.Value, variation-point={short-label=vpOUT_VeCOUB_Cnt_STGFtRfgtShtOffVlv_MFOP_Value, sw-syscond=1}
              OUT_VeCOUB_Cnt_STBFtRfgtShtOffVlv_MFOP_Value: accessed-variable=VeCOUB_Cnt_STBFtRfgtShtOffVlv_MFOP.Value, variation-point={short-label=vpOUT_VeCOUB_Cnt_STBFtRfgtShtOffVlv_MFOP_Value, sw-syscond=1}
              OUT_VeCOUB_Cnt_OCChillrShtOffVlv_MFOP_Value: accessed-variable=VeCOUB_Cnt_OCChillrShtOffVlv_MFOP.Value, variation-point={short-label=vpOUT_VeCOUB_Cnt_OCChillrShtOffVlv_MFOP_Value, sw-syscond=1}
              OUT_VeCOUB_Cnt_STGChillrShtOffVlv_MFOP_Value: accessed-variable=VeCOUB_Cnt_STGChillrShtOffVlv_MFOP.Value, variation-point={short-label=vpOUT_VeCOUB_Cnt_STGChillrShtOffVlv_MFOP_Value, sw-syscond=1}
              OUT_VeCOUB_Cnt_STBChillrShtOffVlv_MFOP_Value: accessed-variable=VeCOUB_Cnt_STBChillrShtOffVlv_MFOP.Value, variation-point={short-label=vpOUT_VeCOUB_Cnt_STBChillrShtOffVlv_MFOP_Value, sw-syscond=1}
              OUT_VeCOUB_Cnt_HiTempShtOffVlvOC_MFOP_Value: accessed-variable=VeCOUB_Cnt_HiTempShtOffVlvOC_MFOP.Value, variation-point={short-label=vpOUT_VeCOUB_Cnt_HiTempShtOffVlvOC_MFOP_Value, sw-syscond=1}
              OUT_VeCOUB_Cnt_HiTempShtOffVlvSTG_MFOP_Value: accessed-variable=VeCOUB_Cnt_HiTempShtOffVlvSTG_MFOP.Value, variation-point={short-label=vpOUT_VeCOUB_Cnt_HiTempShtOffVlvSTG_MFOP_Value, sw-syscond=1}
              OUT_VeCOUB_Cnt_HiTempShtOffVlvSTB_MFOP_Value: accessed-variable=VeCOUB_Cnt_HiTempShtOffVlvSTB_MFOP.Value, variation-point={short-label=vpOUT_VeCOUB_Cnt_HiTempShtOffVlvSTB_MFOP_Value, sw-syscond=1}
          5 x sync call, all with timeout=1E-06:
            SC_COUB_MedTED_StartCheckpoint_CheckpointReached: operation=COUB_MedTED_StartCheckpoint.CheckpointReached
            SC_COUB_MedTED_StopCheckpoint_CheckpointReached: operation=COUB_MedTED_StopCheckpoint.CheckpointReached
            SC_SetDIOR_b_ChillrShtOffVlv_St: operation=SetDIOR_b_ChillrShtOffVlv.St, variation-point={short-label=vpSC_SetDIOR_b_ChillrShtOffVlv_St, sw-syscond=1}
            SC_SetDIOR_b_FrntRefrigShtOffVlv_St: operation=SetDIOR_b_FrntRefrigShtOffVlv.St, variation-point={short-label=vpSC_SetDIOR_b_FrntRefrigShtOffVlv_St, sw-syscond=1}
            SC_SetDIOR_b_SpareHsd3OutpSt_St: operation=SetDIOR_b_SpareHsd3OutpSt.St, variation-point={short-label=vpSC_SetDIOR_b_SpareHsd3OutpSt_St, sw-syscond=1}
        COUB_MedTEH
          data-receive-point-by-arguments:
            26 x access:
              IN_VeAPMR_b_EnblThrmlRelay_Value: accessed-variable=VeAPMR_b_EnblThrmlRelay.Value, variation-point={short-label=vpIN_VeAPMR_b_EnblThrmlRelay_Value, sw-syscond=1}
              IN_VeDFIR_b_DsblDiagFailSafe_Value: accessed-variable=VeDFIR_b_DsblDiagFailSafe.Value, variation-point={short-label=vpIN_VeDFIR_b_DsblDiagFailSafe_Value, sw-syscond=1}
              IN_VeDFIR_b_IsDiagGlobalConditionsValid_Value: accessed-variable=VeDFIR_b_IsDiagGlobalConditionsValid.Value, variation-point={short-label=vpIN_VeDFIR_b_IsDiagGlobalConditionsValid_Value, sw-syscond=1}
              IN_VeDFIR_b_PostCodeClrDiagDsbl_Value: accessed-variable=VeDFIR_b_PostCodeClrDiagDsbl.Value, variation-point={short-label=vpIN_VeDFIR_b_PostCodeClrDiagDsbl_Value, sw-syscond=1}
              IN_VeDIOR_RadrFanCtrlDiagCmn_b_FailrPrsnt: accessed-variable=VeDIOR_RadrFanCtrlDiagCmn.b_FailrPrsnt, variation-point={short-label=vpIN_VeDIOR_RadrFanCtrlDiagCmn_b_FailrPrsnt, sw-syscond=1}
              IN_VeDIOR_RadrFanCtrlFltCircDtctd_CircOpen: accessed-variable=VeDIOR_RadrFanCtrlFltCircDtctd.CircOpen, variation-point={short-label=vpIN_VeDIOR_RadrFanCtrlFltCircDtctd_CircOpen, sw-syscond=1}
              IN_VeDIOR_RadrFanCtrlFltCircDtctd_CircShoHi: accessed-variable=VeDIOR_RadrFanCtrlFltCircDtctd.CircShoHi, variation-point={short-label=vpIN_VeDIOR_RadrFanCtrlFltCircDtctd_CircShoHi, sw-syscond=1}
              IN_VeDIOR_RadrFanCtrlFltCircDtctd_CircShoLo: accessed-variable=VeDIOR_RadrFanCtrlFltCircDtctd.CircShoLo, variation-point={short-label=vpIN_VeDIOR_RadrFanCtrlFltCircDtctd_CircShoLo, sw-syscond=1}
              IN_VeDIOR_Spare4Lsd_PwmOutpDiagCmn_b_FailrPrsnt: accessed-variable=VeDIOR_Spare4Lsd_PwmOutpDiagCmn.b_FailrPrsnt, variation-point={short-label=vpIN_VeDIOR_Spare4Lsd_PwmOutpDiagCmn_b_FailrPrsnt, sw-syscond=1}
              IN_VeDIOR_Spare4Lsd_PwmOutpDiagFltCircDtctd_CircShoHi: accessed-variable=VeDIOR_Spare4Lsd_PwmOutpDiagFltCircDtctd.CircShoHi, variation-point={short-label=vpIN_VeDIOR_Spare4Lsd_PwmOutpDiagFltCircDtctd_CircShoHi, sw-syscond=1}
              IN_VeDIOR_Spare4Lsd_PwmOutpDiagFltCircDtctd_CircShoLo: accessed-variable=VeDIOR_Spare4Lsd_PwmOutpDiagFltCircDtctd.CircShoLo, variation-point={short-label=vpIN_VeDIOR_Spare4Lsd_PwmOutpDiagFltCircDtctd_CircShoLo, sw-syscond=1}
              IN_VeDIOR_ThermSysEnblDiagCmn_b_FailrPrsnt: accessed-variable=VeDIOR_ThermSysEnblDiagCmn.b_FailrPrsnt, variation-point={short-label=vpIN_VeDIOR_ThermSysEnblDiagCmn_b_FailrPrsnt, sw-syscond=1}
              IN_VeDMAB_y_StatusByte_Fan1CntrlCkt_Value: accessed-variable=VeDMAB_y_StatusByte_Fan1CntrlCkt.Value, variation-point={short-label=vpIN_VeDMAB_y_StatusByte_Fan1CntrlCkt_Value, sw-syscond=1}
              IN_VeDMAB_y_StatusByte_Fan1CntrlCktHi_Value: accessed-variable=VeDMAB_y_StatusByte_Fan1CntrlCktHi.Value, variation-point={short-label=vpIN_VeDMAB_y_StatusByte_Fan1CntrlCktHi_Value, sw-syscond=1}
              IN_VeDMAB_y_StatusByte_Fan1CntrlCktLo_Value: accessed-variable=VeDMAB_y_StatusByte_Fan1CntrlCktLo.Value, variation-point={short-label=vpIN_VeDMAB_y_StatusByte_Fan1CntrlCktLo_Value, sw-syscond=1}
              IN_VeDMAB_y_StatusByte_PwrTrnsfrRlyCntrlCktHi_Value: accessed-variable=VeDMAB_y_StatusByte_PwrTrnsfrRlyCntrlCktHi.Value, variation-point={short-label=vpIN_VeDMAB_y_StatusByte_PwrTrnsfrRlyCntrlCktHi_Value, sw-syscond=1}
              IN_VeDMAB_y_StatusByte_PwrTrnsfrRlyCntrlCktLo_Value: accessed-variable=VeDMAB_y_StatusByte_PwrTrnsfrRlyCntrlCktLo.Value, variation-point={short-label=vpIN_VeDMAB_y_StatusByte_PwrTrnsfrRlyCntrlCktLo_Value, sw-syscond=1}
              IN_VeDMAB_y_StatusByte_ThrmlRlyCtrlCkt_Value: accessed-variable=VeDMAB_y_StatusByte_ThrmlRlyCtrlCkt.Value, variation-point={short-label=vpIN_VeDMAB_y_StatusByte_ThrmlRlyCtrlCkt_Value, sw-syscond=1}
              IN_VeFSCR_Pct_RadFanCmd_Value: accessed-variable=VeFSCR_Pct_RadFanCmd.Value, variation-point={short-label=vpIN_VeFSCR_Pct_RadFanCmd_Value, sw-syscond=1}
              IN_VeNVMB_Cnt_ACSwitchRelaySTB_MFOP_Value: accessed-variable=VeNVMB_Cnt_ACSwitchRelaySTB_MFOP.Value, variation-point={short-label=vpIN_VeNVMB_Cnt_ACSwitchRelaySTB_MFOP_Value, sw-syscond=1}
              IN_VeNVMB_Cnt_ACSwitchRelaySTG_MFOP_Value: accessed-variable=VeNVMB_Cnt_ACSwitchRelaySTG_MFOP.Value, variation-point={short-label=vpIN_VeNVMB_Cnt_ACSwitchRelaySTG_MFOP_Value, sw-syscond=1}
              IN_VeNVMB_Cnt_RadrFanCtrlOC_MFOP_Value: accessed-variable=VeNVMB_Cnt_RadrFanCtrlOC_MFOP.Value, variation-point={short-label=vpIN_VeNVMB_Cnt_RadrFanCtrlOC_MFOP_Value, sw-syscond=1}
              IN_VeNVMB_Cnt_RadrFanCtrlSTB_MFOP_Value: accessed-variable=VeNVMB_Cnt_RadrFanCtrlSTB_MFOP.Value, variation-point={short-label=vpIN_VeNVMB_Cnt_RadrFanCtrlSTB_MFOP_Value, sw-syscond=1}
              IN_VeNVMB_Cnt_RadrFanCtrlSTG_MFOP_Value: accessed-variable=VeNVMB_Cnt_RadrFanCtrlSTG_MFOP.Value, variation-point={short-label=vpIN_VeNVMB_Cnt_RadrFanCtrlSTG_MFOP_Value, sw-syscond=1}
              IN_VeNVMB_Cnt_ThermSysEnbl_MFOP_Value: accessed-variable=VeNVMB_Cnt_ThermSysEnbl_MFOP.Value, variation-point={short-label=vpIN_VeNVMB_Cnt_ThermSysEnbl_MFOP_Value, sw-syscond=1}
              IN_VeVTLR_b_ACSw_Cmd_Value: accessed-variable=VeVTLR_b_ACSw_Cmd.Value, variation-point={short-label=vpIN_VeVTLR_b_ACSw_Cmd_Value, sw-syscond=1}
          data-send-points:
            18 x access:
              OUT_VeCOUB_b_DiagFA_WakeupThermalCtrl_Value: accessed-variable=VeCOUB_b_DiagFA_WakeupThermalCtrl.Value, variation-point={short-label=vpOUT_VeCOUB_b_DiagFA_WakeupThermalCtrl_Value, sw-syscond=1}
              OUT_VeCOUB_b_OCDiagFA_RadFanCmd_Value: accessed-variable=VeCOUB_b_OCDiagFA_RadFanCmd.Value, variation-point={short-label=vpOUT_VeCOUB_b_OCDiagFA_RadFanCmd_Value, sw-syscond=1}
              OUT_VeCOUB_b_STGDiagFA_RadFanCmd_Value: accessed-variable=VeCOUB_b_STGDiagFA_RadFanCmd.Value, variation-point={short-label=vpOUT_VeCOUB_b_STGDiagFA_RadFanCmd_Value, sw-syscond=1}
              OUT_VeCOUB_b_STBDiagFA_RadFanCmd_Value: accessed-variable=VeCOUB_b_STBDiagFA_RadFanCmd.Value, variation-point={short-label=vpOUT_VeCOUB_b_STBDiagFA_RadFanCmd_Value, sw-syscond=1}
              OUT_VeCOUB_e_FaultSts_ThrmlRlyCtrlCkt_Value: accessed-variable=VeCOUB_e_FaultSts_ThrmlRlyCtrlCkt.Value, variation-point={short-label=vpOUT_VeCOUB_e_FaultSts_ThrmlRlyCtrlCkt_Value, sw-syscond=1}
              OUT_VeCOUB_e_FaultSts_Fan1CntrlCkt_Value: accessed-variable=VeCOUB_e_FaultSts_Fan1CntrlCkt.Value, variation-point={short-label=vpOUT_VeCOUB_e_FaultSts_Fan1CntrlCkt_Value, sw-syscond=1}
              OUT_VeCOUB_e_FaultSts_Fan1CntrlCktLo_Value: accessed-variable=VeCOUB_e_FaultSts_Fan1CntrlCktLo.Value, variation-point={short-label=vpOUT_VeCOUB_e_FaultSts_Fan1CntrlCktLo_Value, sw-syscond=1}
              OUT_VeCOUB_e_FaultSts_Fan1CntrlCktHi_Value: accessed-variable=VeCOUB_e_FaultSts_Fan1CntrlCktHi.Value, variation-point={short-label=vpOUT_VeCOUB_e_FaultSts_Fan1CntrlCktHi_Value, sw-syscond=1}
              OUT_VeCOUB_b_STGDiagFA_ACSwitchRelay_Value: accessed-variable=VeCOUB_b_STGDiagFA_ACSwitchRelay.Value, variation-point={short-label=vpOUT_VeCOUB_b_STGDiagFA_ACSwitchRelay_Value, sw-syscond=1}
              OUT_VeCOUB_b_STBDiagFA_ACSwitchRelay_Value: accessed-variable=VeCOUB_b_STBDiagFA_ACSwitchRelay.Value, variation-point={short-label=vpOUT_VeCOUB_b_STBDiagFA_ACSwitchRelay_Value, sw-syscond=1}
              OUT_VeCOUB_e_FaultSts_PwrTrnsfrRlyCntrlCktLo_Value: accessed-variable=VeCOUB_e_FaultSts_PwrTrnsfrRlyCntrlCktLo.Value, variation-point={short-label=vpOUT_VeCOUB_e_FaultSts_PwrTrnsfrRlyCntrlCktLo_Value, sw-syscond=1}
              OUT_VeCOUB_e_FaultSts_PwrTrnsfrRlyCntrlCktHi_Value: accessed-variable=VeCOUB_e_FaultSts_PwrTrnsfrRlyCntrlCktHi.Value, variation-point={short-label=vpOUT_VeCOUB_e_FaultSts_PwrTrnsfrRlyCntrlCktHi_Value, sw-syscond=1}
              OUT_VeCOUB_Cnt_ThermSysEnbl_MFOP_Value: accessed-variable=VeCOUB_Cnt_ThermSysEnbl_MFOP.Value, variation-point={short-label=vpOUT_VeCOUB_Cnt_ThermSysEnbl_MFOP_Value, sw-syscond=1}
              OUT_VeCOUB_Cnt_RadrFanCtrlOC_MFOP_Value: accessed-variable=VeCOUB_Cnt_RadrFanCtrlOC_MFOP.Value, variation-point={short-label=vpOUT_VeCOUB_Cnt_RadrFanCtrlOC_MFOP_Value, sw-syscond=1}
              OUT_VeCOUB_Cnt_RadrFanCtrlSTG_MFOP_Value: accessed-variable=VeCOUB_Cnt_RadrFanCtrlSTG_MFOP.Value, variation-point={short-label=vpOUT_VeCOUB_Cnt_RadrFanCtrlSTG_MFOP_Value, sw-syscond=1}
              OUT_VeCOUB_Cnt_RadrFanCtrlSTB_MFOP_Value: accessed-variable=VeCOUB_Cnt_RadrFanCtrlSTB_MFOP.Value, variation-point={short-label=vpOUT_VeCOUB_Cnt_RadrFanCtrlSTB_MFOP_Value, sw-syscond=1}
              OUT_VeCOUB_Cnt_ACSwitchRelaySTG_MFOP_Value: accessed-variable=VeCOUB_Cnt_ACSwitchRelaySTG_MFOP.Value, variation-point={short-label=vpOUT_VeCOUB_Cnt_ACSwitchRelaySTG_MFOP_Value, sw-syscond=1}
              OUT_VeCOUB_Cnt_ACSwitchRelaySTB_MFOP_Value: accessed-variable=VeCOUB_Cnt_ACSwitchRelaySTB_MFOP.Value, variation-point={short-label=vpOUT_VeCOUB_Cnt_ACSwitchRelaySTB_MFOP_Value, sw-syscond=1}
          5 x sync call, all with timeout=1E-06:
            SC_COUB_MedTEH_StartCheckpoint_CheckpointReached: operation=COUB_MedTEH_StartCheckpoint.CheckpointReached
            SC_COUB_MedTEH_StopCheckpoint_CheckpointReached: operation=COUB_MedTEH_StopCheckpoint.CheckpointReached
            SC_SetDIOR_b_ThermSysEnbl_St: operation=SetDIOR_b_ThermSysEnbl.St, variation-point={short-label=vpSC_SetDIOR_b_ThermSysEnbl_St, sw-syscond=1}
            SC_SetDIOR_e_RadrFanCtrl_SetDIOR_PWM_DC: operation=SetDIOR_e_RadrFanCtrl.SetDIOR_PWM_DC, variation-point={short-label=vpSC_SetDIOR_e_RadrFanCtrl_SetDIOR_PWM_DC, sw-syscond=1}
            SC_SetDIOR_e_Spare4Lsd_PwmOutpOps_SetDIOR_PWM_DC: operation=SetDIOR_e_Spare4Lsd_PwmOutpOps.SetDIOR_PWM_DC, variation-point={short-label=vpSC_SetDIOR_e_Spare4Lsd_PwmOutpOps_SetDIOR_PWM_DC, sw-syscond=1}
        COUB_MedTEB
          sync call SC_COUB_MedTEB_StartCheckpoint_CheckpointReached: operation=COUB_MedTEB_StartCheckpoint.CheckpointReached, timeout=1E-06
          sync call SC_COUB_MedTEB_StopCheckpoint_CheckpointReached: operation=COUB_MedTEB_StopCheckpoint.CheckpointReached, timeout=1E-06
      13 x variation point proxy, all with category=CONDITION:
        Variant_COUB_ACPWRSWRLY_Presence: condition-access=1
        Variant_COUB_CNTCTRCMD_Presence: condition-access=0
        Variant_COUB_CSOV_Presence: condition-access=1
        Variant_COUB_EPTWUP_Presence: condition-access=0
        Variant_COUB_FRSOV_Presence: condition-access=1
        Variant_COUB_HTSOV_Presence: condition-access=1
        Variant_COUB_OILPUMPRLY_Presence: condition-access=0
        Variant_COUB_OILPUMP_Presence: condition-access=0
        Variant_COUB_PCURLYCNTRL_Presence: condition-access=0
        Variant_COUB_POWERPANELBOX_Presence: condition-access=0
        Variant_COUB_POWERPANELLED_Presence: condition-access=0
        Variant_COUB_RADFAN_Presence: condition-access=1
        Variant_COUB_THRMLSYSEN_Presence: condition-access=1
